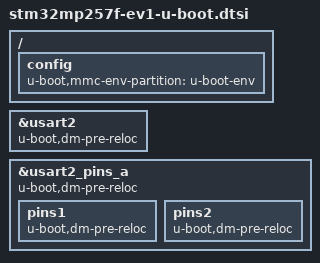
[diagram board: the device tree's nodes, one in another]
// SPDX-License-Identifier: GPL-2.0-or-later OR BSD-3-Clause
/*
 * Copyright (C) STMicroelectronics 2021 - All Rights Reserved
 */

#include "stm32mp25-u-boot.dtsi"

/ {
	config {
		u-boot,mmc-env-partition = "u-boot-env";
	};
};

&usart2 {
	u-boot,dm-pre-reloc;
};

&usart2_pins_a {
	u-boot,dm-pre-reloc;
	pins1 {
		u-boot,dm-pre-reloc;
	};
	pins2 {
		u-boot,dm-pre-reloc;
	};
};
